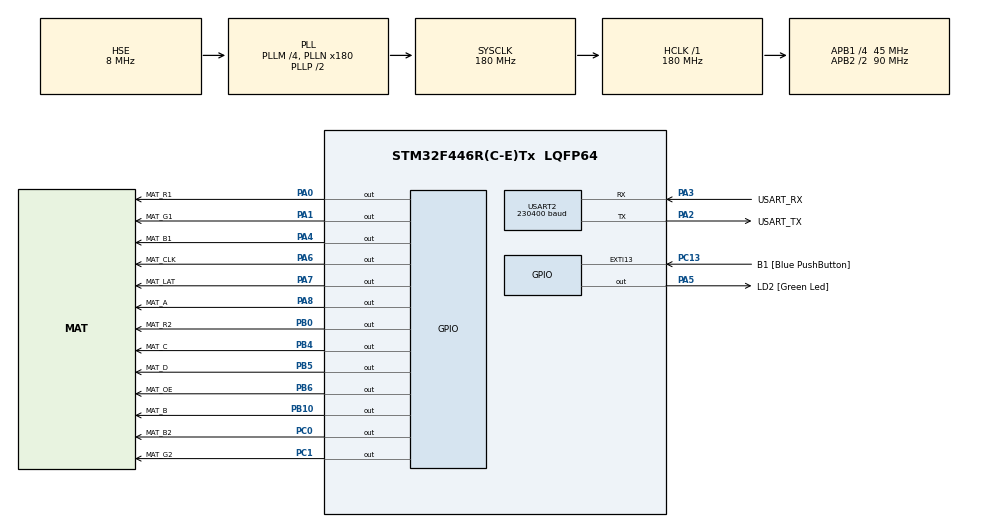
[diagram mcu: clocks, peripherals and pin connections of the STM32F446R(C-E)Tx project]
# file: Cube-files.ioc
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Dma.Request0=USART2_TX
Dma.USART2_TX.0.Direction=DMA_MEMORY_TO_PERIPH
Dma.USART2_TX.0.FIFOMode=DMA_FIFOMODE_DISABLE
Dma.USART2_TX.0.Instance=DMA1_Stream6
Dma.USART2_TX.0.MemDataAlignment=DMA_MDATAALIGN_BYTE
Dma.USART2_TX.0.MemInc=DMA_MINC_ENABLE
Dma.USART2_TX.0.Mode=DMA_NORMAL
Dma.USART2_TX.0.PeriphDataAlignment=DMA_PDATAALIGN_BYTE
Dma.USART2_TX.0.PeriphInc=DMA_PINC_DISABLE
Dma.USART2_TX.0.Priority=DMA_PRIORITY_LOW
Mcu.Family=STM32F4
Mcu.Name=STM32F446R(C-E)Tx
Mcu.Package=LQFP64
NVIC.DMA1_Stream6_IRQn=true\:0\:0\:false\:false\:true\:false\:true\:true
NVIC.PriorityGroup=NVIC_PRIORITYGROUP_0
NVIC.TIM2_IRQn=true\:0\:0\:false\:false\:true\:true\:true\:true
PA0-WKUP.GPIO_Label=MAT_R1
PA0-WKUP.GPIO_Speed=GPIO_SPEED_FREQ_VERY_HIGH
PA0-WKUP.Signal=GPIO_Output
PA1.GPIO_Label=MAT_G1
PA1.GPIO_Speed=GPIO_SPEED_FREQ_VERY_HIGH
PA1.Signal=GPIO_Output
PA13.GPIO_Label=TMS
PA13.Mode=Serial_Wire
PA13.Signal=SYS_JTMS-SWDIO
PA14.GPIO_Label=TCK
PA14.Mode=Serial_Wire
PA14.Signal=SYS_JTCK-SWCLK
PA2.GPIO_Label=USART_TX
PA2.Mode=Asynchronous
PA2.Signal=USART2_TX
PA3.GPIO_Label=USART_RX
PA3.Mode=Asynchronous
PA3.Signal=USART2_RX
PA4.GPIO_Label=MAT_B1
PA4.GPIO_Speed=GPIO_SPEED_FREQ_VERY_HIGH
PA4.Signal=GPIO_Output
PA5.GPIO_Label=LD2 [Green Led]
PA5.Signal=GPIO_Output
PA6.GPIO_Label=MAT_CLK
PA6.GPIO_Speed=GPIO_SPEED_FREQ_VERY_HIGH
PA6.Signal=GPIO_Output
PA7.GPIO_Label=MAT_LAT
PA7.GPIO_Speed=GPIO_SPEED_FREQ_VERY_HIGH
PA7.Signal=GPIO_Output
PA8.GPIO_Label=MAT_A
PA8.GPIO_Speed=GPIO_SPEED_FREQ_VERY_HIGH
PA8.Signal=GPIO_Output
PB0.GPIO_Label=MAT_R2
PB0.GPIO_Speed=GPIO_SPEED_FREQ_VERY_HIGH
PB0.Signal=GPIO_Output
PB10.GPIO_Label=MAT_B
PB10.GPIO_Speed=GPIO_SPEED_FREQ_VERY_HIGH
PB10.Signal=GPIO_Output
PB3.GPIO_Label=SWO
PB3.Signal=SYS_JTDO-SWO
PB4.GPIO_Label=MAT_C
PB4.GPIO_Speed=GPIO_SPEED_FREQ_VERY_HIGH
PB4.Signal=GPIO_Output
PB5.GPIO_Label=MAT_D
PB5.GPIO_Speed=GPIO_SPEED_FREQ_VERY_HIGH
PB5.Signal=GPIO_Output
PB6.GPIO_Label=MAT_OE
PB6.GPIO_PuPd=GPIO_NOPULL
PB6.GPIO_Speed=GPIO_SPEED_FREQ_VERY_HIGH
PB6.PinState=GPIO_PIN_SET
PB6.Signal=GPIO_Output
PC0.GPIO_Label=MAT_B2
PC0.GPIO_Speed=GPIO_SPEED_FREQ_VERY_HIGH
PC0.Signal=GPIO_Output
PC1.GPIO_Label=MAT_G2
PC1.GPIO_Speed=GPIO_SPEED_FREQ_VERY_HIGH
PC1.Signal=GPIO_Output
PC13.GPIO_Label=B1 [Blue PushButton]
PC13.GPIO_ModeDefaultEXTI=GPIO_MODE_IT_FALLING
PC13.Signal=GPXTI13
PC14-OSC32_IN.Mode=LSE-External-Oscillator
PC14-OSC32_IN.Signal=RCC_OSC32_IN
PC15-OSC32_OUT.Mode=LSE-External-Oscillator
PC15-OSC32_OUT.Signal=RCC_OSC32_OUT
PH0-OSC_IN.Mode=HSE-External-Oscillator
PH0-OSC_IN.Signal=RCC_OSC_IN
PH1-OSC_OUT.Mode=HSE-External-Oscillator
PH1-OSC_OUT.Signal=RCC_OSC_OUT
ProjectManager.HeapSize=0x200
ProjectManager.StackSize=0x400
ProjectManager.TargetToolchain=Makefile
RCC.48MHZClocksFreq_Value=84000000
RCC.AHBFreq_Value=180000000
RCC.APB1CLKDivider=RCC_HCLK_DIV4
RCC.APB1Freq_Value=45000000
RCC.APB1TimFreq_Value=90000000
RCC.APB2CLKDivider=RCC_HCLK_DIV2
RCC.APB2Freq_Value=90000000
RCC.APB2TimFreq_Value=180000000
RCC.CortexFreq_Value=180000000
RCC.FLatency-AdvancedSettings=FLASH_LATENCY_5
RCC.HCLKFreq_Value=180000000
RCC.HSE_VALUE=8000000
RCC.HSI_VALUE=16000000
RCC.PLLM=4
RCC.PLLN=180
RCC.PLLSourceVirtual=RCC_PLLSOURCE_HSE
RCC.SYSCLKFreq_VALUE=180000000
RCC.SYSCLKSource=RCC_SYSCLKSOURCE_PLLCLK
RCC.USBFreq_Value=180000000
RCC.VCOOutputFreq_Value=360000000
TIM2.AutoReloadPreload=TIM_AUTORELOAD_PRELOAD_ENABLE
TIM2.Period=50
TIM2.Prescaler=89
TIM5.Prescaler=89
USART2.BaudRate=230400
USART2.VirtualMode=VM_ASYNC
VP_TIM2_VS_ClockSourceINT.Mode=Internal
VP_TIM5_VS_ClockSourceINT.Mode=Internal
board=NUCLEO-F446RE

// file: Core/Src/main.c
/* USER CODE BEGIN Header */
/**
  ******************************************************************************
  * @file           : main.c
  * @brief          : Main program body
  ******************************************************************************
  * @attention
  *
  * Copyright (c) 2024 STMicroelectronics.
  * All rights reserved.
  *
  * This software is licensed under terms that can be found in the LICENSE file
  * in the root directory of this software component.
  * If no LICENSE file comes with this software, it is provided AS-IS.
  *
  ******************************************************************************
  */
/* USER CODE END Header */
#include "main.h"
#include "dma.h"
#include "tim.h"
#include "usart.h"
#include "gpio.h"

/* USER CODE BEGIN Includes */
#include "userInit.h"
#include "led.h"
/* USER CODE END Includes */

void SystemClock_Config(void);

int main(void)
{

  /* MCU Configuration--------------------------------------------------------*/

  /* Reset of all peripherals, Initializes the Flash interface and the Systick. */
  HAL_Init();

  /* Configure the system clock */
  SystemClock_Config();

  /* Initialize all configured peripherals */
  MX_GPIO_Init();
  MX_DMA_Init();
  MX_USART2_UART_Init();
  MX_TIM5_Init();
  MX_TIM2_Init();
  /* USER CODE BEGIN 2 */
  userInit();
  test_led();
  /* USER CODE END 2 */

  /* Infinite loop */
  while (1)
  {

  }
}

void SystemClock_Config(void)
{
  RCC_OscInitTypeDef RCC_OscInitStruct = {0};
  RCC_ClkInitTypeDef RCC_ClkInitStruct = {0};

  /** Configure the main internal regulator output voltage
  */
  __HAL_RCC_PWR_CLK_ENABLE();
  __HAL_PWR_VOLTAGESCALING_CONFIG(PWR_REGULATOR_VOLTAGE_SCALE1);

  /** Initializes the RCC Oscillators according to the specified parameters
  * in the RCC_OscInitTypeDef structure.
  */
  RCC_OscInitStruct.OscillatorType = RCC_OSCILLATORTYPE_HSE;
  RCC_OscInitStruct.HSEState = RCC_HSE_ON;
  RCC_OscInitStruct.PLL.PLLState = RCC_PLL_ON;
  RCC_OscInitStruct.PLL.PLLSource = RCC_PLLSOURCE_HSE;
  RCC_OscInitStruct.PLL.PLLM = 4;
  RCC_OscInitStruct.PLL.PLLN = 180;
  RCC_OscInitStruct.PLL.PLLP = RCC_PLLP_DIV2;
  RCC_OscInitStruct.PLL.PLLQ = 2;
  RCC_OscInitStruct.PLL.PLLR = 2;
  if (HAL_RCC_OscConfig(&RCC_OscInitStruct) != HAL_OK)
  {
    Error_Handler();
  }

  /** Activate the Over-Drive mode
  */
  if (HAL_PWREx_EnableOverDrive() != HAL_OK)
  {
    Error_Handler();
  }

  /** Initializes the CPU, AHB and APB buses clocks
  */
  RCC_ClkInitStruct.ClockType = RCC_CLOCKTYPE_HCLK|RCC_CLOCKTYPE_SYSCLK
                              |RCC_CLOCKTYPE_PCLK1|RCC_CLOCKTYPE_PCLK2;
  RCC_ClkInitStruct.SYSCLKSource = RCC_SYSCLKSOURCE_PLLCLK;
  RCC_ClkInitStruct.AHBCLKDivider = RCC_SYSCLK_DIV1;
  RCC_ClkInitStruct.APB1CLKDivider = RCC_HCLK_DIV4;
  RCC_ClkInitStruct.APB2CLKDivider = RCC_HCLK_DIV2;

  if (HAL_RCC_ClockConfig(&RCC_ClkInitStruct, FLASH_LATENCY_5) != HAL_OK)
  {
    Error_Handler();
  }
}

void Error_Handler(void)
{
  __disable_irq();
  while (1)
  {
  }
}
